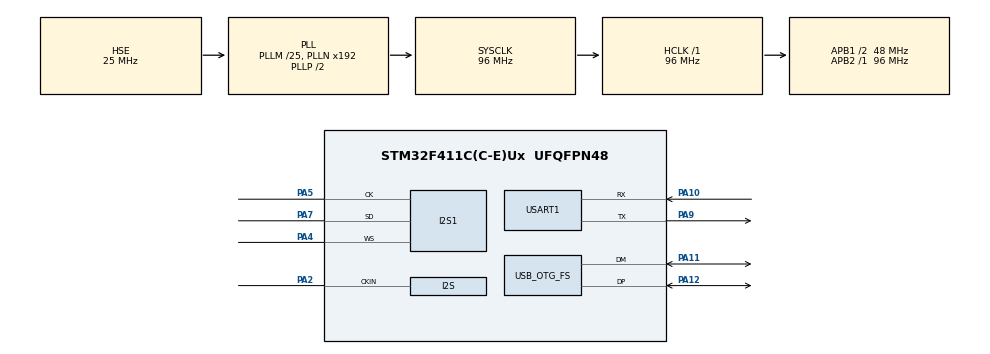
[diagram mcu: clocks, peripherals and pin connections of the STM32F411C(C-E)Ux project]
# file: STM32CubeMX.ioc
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Dma.Request0=SPI1_RX
Dma.SPI1_RX.0.Direction=DMA_PERIPH_TO_MEMORY
Dma.SPI1_RX.0.FIFOMode=DMA_FIFOMODE_ENABLE
Dma.SPI1_RX.0.FIFOThreshold=DMA_FIFO_THRESHOLD_HALFFULL
Dma.SPI1_RX.0.Instance=DMA2_Stream0
Dma.SPI1_RX.0.MemBurst=DMA_MBURST_SINGLE
Dma.SPI1_RX.0.MemDataAlignment=DMA_MDATAALIGN_HALFWORD
Dma.SPI1_RX.0.MemInc=DMA_MINC_ENABLE
Dma.SPI1_RX.0.Mode=DMA_CIRCULAR
Dma.SPI1_RX.0.PeriphBurst=DMA_PBURST_SINGLE
Dma.SPI1_RX.0.PeriphDataAlignment=DMA_PDATAALIGN_HALFWORD
Dma.SPI1_RX.0.PeriphInc=DMA_PINC_DISABLE
Dma.SPI1_RX.0.Priority=DMA_PRIORITY_HIGH
I2S1.AudioFreq=I2S_AUDIOFREQ_96K
I2S1.ClockSource=I2S_CLOCK_EXTERNAL
I2S1.DataFormat=I2S_DATAFORMAT_24B
I2S1.ErrorAudioFreq=-8.12 %
I2S1.FullDuplexMode=I2S_FULLDUPLEXMODE_DISABLE
I2S1.Instance=SPI$Index
I2S1.Mode=I2S_MODE_SLAVE_RX
I2S1.RealAudioFreq=88.2 KHz
I2S1.VirtualMode=I2S_MODE_SLAVE
Mcu.Family=STM32F4
Mcu.Name=STM32F411C(C-E)Ux
Mcu.Package=UFQFPN48
NVIC.DMA2_Stream0_IRQn=true\:8\:0\:true\:false\:true\:false\:true\:true
NVIC.PriorityGroup=NVIC_PRIORITYGROUP_4
NVIC.TIM5_IRQn=true\:15\:0\:false\:false\:true\:false\:true\:true
NVIC.TimeBase=TIM5_IRQn
NVIC.TimeBaseIP=TIM5
PA10.Mode=Asynchronous
PA10.Signal=USART1_RX
PA11.Mode=Device_Only
PA11.Signal=USB_OTG_FS_DM
PA12.Mode=Device_Only
PA12.Signal=USB_OTG_FS_DP
PA13.Mode=Serial_Wire
PA13.Signal=SYS_JTMS-SWDIO
PA14.Mode=Serial_Wire
PA14.Signal=SYS_JTCK-SWCLK
PA2.Mode=Audio_ClockIn
PA2.Signal=I2S_CKIN
PA4.Mode=Half_Duplex_Slave
PA4.Signal=I2S1_WS
PA5.Mode=Half_Duplex_Slave
PA5.Signal=I2S1_CK
PA7.Mode=Half_Duplex_Slave
PA7.Signal=I2S1_SD
PA9.Mode=Asynchronous
PA9.Signal=USART1_TX
PC14-OSC32_IN.Mode=LSE-External-Oscillator
PC14-OSC32_IN.Signal=RCC_OSC32_IN
PC15-OSC32_OUT.Mode=LSE-External-Oscillator
PC15-OSC32_OUT.Signal=RCC_OSC32_OUT
PH0\ -\ OSC_IN.Mode=HSE-External-Oscillator
PH0\ -\ OSC_IN.Signal=RCC_OSC_IN
PH1\ -\ OSC_OUT.Mode=HSE-External-Oscillator
PH1\ -\ OSC_OUT.Signal=RCC_OSC_OUT
ProjectManager.HeapSize=0x400
ProjectManager.StackSize=0x400
ProjectManager.TargetToolchain=MDK-ARM V5
RCC.48MHZClocksFreq_Value=48000000
RCC.AHBFreq_Value=96000000
RCC.APB1CLKDivider=RCC_HCLK_DIV2
RCC.APB1Freq_Value=48000000
RCC.APB1TimFreq_Value=96000000
RCC.APB2Freq_Value=96000000
RCC.APB2TimFreq_Value=96000000
RCC.CortexFreq_Value=96000000
RCC.EXTERNAL_CLOCK_VALUE=24567000
RCC.HCLKFreq_Value=96000000
RCC.HSE_VALUE=25000000
RCC.HSI_VALUE=16000000
RCC.I2SClockSource=I2S_CLOCK_EXTERNAL
RCC.PLLM=25
RCC.SYSCLKFreq_VALUE=96000000
RCC.SYSCLKSource=RCC_SYSCLKSOURCE_PLLCLK
RCC.VCOOutputFreq_Value=192000000
RTC.Format=RTC_FORMAT_BCD
USART1.VirtualMode=VM_ASYNC
USB_OTG_FS.VirtualMode=Device_Only
VP_RTC_VS_RTC_Activate.Mode=RTC_Enabled
VP_RTC_VS_RTC_Calendar.Mode=RTC_Calendar
VP_SYS_VS_tim5.Mode=TIM5
board=custom

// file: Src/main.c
/* USER CODE BEGIN Header */
/**
  ******************************************************************************
  * @file           : main.c
  * @brief          : Main program body
  ******************************************************************************
  * @attention
  *
  * Copyright (c) 2026 STMicroelectronics.
  * All rights reserved.
  *
  * This software is licensed under terms that can be found in the LICENSE file
  * in the root directory of this software component.
  * If no LICENSE file comes with this software, it is provided AS-IS.
  *
  ******************************************************************************
  */
/* USER CODE END Header */
#include "main.h"

I2S_HandleTypeDef hi2s1;
DMA_HandleTypeDef hdma_spi1_rx;

RTC_HandleTypeDef hrtc;

UART_HandleTypeDef huart1;

PCD_HandleTypeDef hpcd_USB_OTG_FS;

void SystemClock_Config(void);
static void MX_GPIO_Init(void);
static void MX_DMA_Init(void);
static void MX_RTC_Init(void);
static void MX_USART1_UART_Init(void);
static void MX_USB_OTG_FS_PCD_Init(void);
static void MX_I2S1_Init(void);
/* USER CODE BEGIN PFP */
extern void app_main(void);
/* USER CODE END PFP */

int main(void)
{

  /* MCU Configuration--------------------------------------------------------*/

  /* Reset of all peripherals, Initializes the Flash interface and the Systick. */
  HAL_Init();

  /* Configure the system clock */
  SystemClock_Config();

  /* USER CODE BEGIN SysInit */
  // 在 main 或时钟初始化后
  CoreDebug->DEMCR |= CoreDebug_DEMCR_TRCENA_Msk;  // 或 (*(volatile U32*)0xE000EDFC) |= (1<<24);
  DWT->CYCCNT = 0;
  DWT->CTRL  |= DWT_CTRL_CYCCNTENA_Msk;            // 或 DWT->CTRL |= (1 << 0);
  /* USER CODE END SysInit */

  /* Initialize all configured peripherals */
  MX_GPIO_Init();
  MX_DMA_Init();
  MX_RTC_Init();
  MX_USART1_UART_Init();
  MX_USB_OTG_FS_PCD_Init();
  MX_I2S1_Init();
  /* USER CODE BEGIN 2 */
  app_main();
  /* USER CODE END 2 */

  /* Infinite loop */
  while (1)
  {

  }
}

void SystemClock_Config(void)
{
  RCC_OscInitTypeDef RCC_OscInitStruct = {0};
  RCC_ClkInitTypeDef RCC_ClkInitStruct = {0};

  /** Configure the main internal regulator output voltage
  */
  __HAL_RCC_PWR_CLK_ENABLE();
  __HAL_PWR_VOLTAGESCALING_CONFIG(PWR_REGULATOR_VOLTAGE_SCALE1);

  /** Initializes the RCC Oscillators according to the specified parameters
  * in the RCC_OscInitTypeDef structure.
  */
  RCC_OscInitStruct.OscillatorType = RCC_OSCILLATORTYPE_LSI|RCC_OSCILLATORTYPE_HSE;
  RCC_OscInitStruct.HSEState = RCC_HSE_ON;
  RCC_OscInitStruct.LSIState = RCC_LSI_ON;
  RCC_OscInitStruct.PLL.PLLState = RCC_PLL_ON;
  RCC_OscInitStruct.PLL.PLLSource = RCC_PLLSOURCE_HSE;
  RCC_OscInitStruct.PLL.PLLM = 25;
  RCC_OscInitStruct.PLL.PLLN = 192;
  RCC_OscInitStruct.PLL.PLLP = RCC_PLLP_DIV2;
  RCC_OscInitStruct.PLL.PLLQ = 4;
  if (HAL_RCC_OscConfig(&RCC_OscInitStruct) != HAL_OK)
  {
    Error_Handler();
  }

  /** Initializes the CPU, AHB and APB buses clocks
  */
  RCC_ClkInitStruct.ClockType = RCC_CLOCKTYPE_HCLK|RCC_CLOCKTYPE_SYSCLK
                              |RCC_CLOCKTYPE_PCLK1|RCC_CLOCKTYPE_PCLK2;
  RCC_ClkInitStruct.SYSCLKSource = RCC_SYSCLKSOURCE_PLLCLK;
  RCC_ClkInitStruct.AHBCLKDivider = RCC_SYSCLK_DIV1;
  RCC_ClkInitStruct.APB1CLKDivider = RCC_HCLK_DIV2;
  RCC_ClkInitStruct.APB2CLKDivider = RCC_HCLK_DIV1;

  if (HAL_RCC_ClockConfig(&RCC_ClkInitStruct, FLASH_LATENCY_3) != HAL_OK)
  {
    Error_Handler();
  }
}

static void MX_I2S1_Init(void)
{

  hi2s1.Instance = SPI1;
  hi2s1.Init.Mode = I2S_MODE_SLAVE_RX;
  hi2s1.Init.Standard = I2S_STANDARD_PHILIPS;
  hi2s1.Init.DataFormat = I2S_DATAFORMAT_24B;
  hi2s1.Init.MCLKOutput = I2S_MCLKOUTPUT_DISABLE;
  hi2s1.Init.AudioFreq = I2S_AUDIOFREQ_96K;
  hi2s1.Init.CPOL = I2S_CPOL_LOW;
  hi2s1.Init.ClockSource = I2S_CLOCK_EXTERNAL;
  hi2s1.Init.FullDuplexMode = I2S_FULLDUPLEXMODE_DISABLE;
  if (HAL_I2S_Init(&hi2s1) != HAL_OK)
  {
    Error_Handler();
  }

}

static void MX_RTC_Init(void)
{

  RTC_TimeTypeDef sTime = {0};
  RTC_DateTypeDef sDate = {0};

  /** Initialize RTC Only
  */
  hrtc.Instance = RTC;
  hrtc.Init.HourFormat = RTC_HOURFORMAT_24;
  hrtc.Init.AsynchPrediv = 127;
  hrtc.Init.SynchPrediv = 255;
  hrtc.Init.OutPut = RTC_OUTPUT_DISABLE;
  hrtc.Init.OutPutPolarity = RTC_OUTPUT_POLARITY_HIGH;
  hrtc.Init.OutPutType = RTC_OUTPUT_TYPE_OPENDRAIN;
  if (HAL_RTC_Init(&hrtc) != HAL_OK)
  {
    Error_Handler();
  }

  /** Initialize RTC and set the Time and Date
  */
  sTime.Hours = 0x0;
  sTime.Minutes = 0x0;
  sTime.Seconds = 0x0;
  sTime.DayLightSaving = RTC_DAYLIGHTSAVING_NONE;
  sTime.StoreOperation = RTC_STOREOPERATION_RESET;
  if (HAL_RTC_SetTime(&hrtc, &sTime, RTC_FORMAT_BCD) != HAL_OK)
  {
    Error_Handler();
  }
  sDate.WeekDay = RTC_WEEKDAY_MONDAY;
  sDate.Month = RTC_MONTH_JANUARY;
  sDate.Date = 0x1;
  sDate.Year = 0x0;

  if (HAL_RTC_SetDate(&hrtc, &sDate, RTC_FORMAT_BCD) != HAL_OK)
  {
    Error_Handler();
  }

}

static void MX_USART1_UART_Init(void)
{

  huart1.Instance = USART1;
  huart1.Init.BaudRate = 115200;
  huart1.Init.WordLength = UART_WORDLENGTH_8B;
  huart1.Init.StopBits = UART_STOPBITS_1;
  huart1.Init.Parity = UART_PARITY_NONE;
  huart1.Init.Mode = UART_MODE_TX_RX;
  huart1.Init.HwFlowCtl = UART_HWCONTROL_NONE;
  huart1.Init.OverSampling = UART_OVERSAMPLING_16;
  if (HAL_UART_Init(&huart1) != HAL_OK)
  {
    Error_Handler();
  }

}

static void MX_USB_OTG_FS_PCD_Init(void)
{

  hpcd_USB_OTG_FS.Instance = USB_OTG_FS;
  hpcd_USB_OTG_FS.Init.dev_endpoints = 4;
  hpcd_USB_OTG_FS.Init.speed = PCD_SPEED_FULL;
  hpcd_USB_OTG_FS.Init.dma_enable = DISABLE;
  hpcd_USB_OTG_FS.Init.phy_itface = PCD_PHY_EMBEDDED;
  hpcd_USB_OTG_FS.Init.Sof_enable = DISABLE;
  hpcd_USB_OTG_FS.Init.low_power_enable = DISABLE;
  hpcd_USB_OTG_FS.Init.lpm_enable = DISABLE;
  hpcd_USB_OTG_FS.Init.vbus_sensing_enable = DISABLE;
  hpcd_USB_OTG_FS.Init.use_dedicated_ep1 = DISABLE;
  if (HAL_PCD_Init(&hpcd_USB_OTG_FS) != HAL_OK)
  {
    Error_Handler();
  }

}

static void MX_DMA_Init(void)
{

  /* DMA controller clock enable */
  __HAL_RCC_DMA2_CLK_ENABLE();

  /* DMA interrupt init */
  /* DMA2_Stream0_IRQn interrupt configuration */
  HAL_NVIC_SetPriority(DMA2_Stream0_IRQn, 8, 0);
  HAL_NVIC_EnableIRQ(DMA2_Stream0_IRQn);

}

static void MX_GPIO_Init(void)
{
  GPIO_InitTypeDef GPIO_InitStruct = {0};

  /* GPIO Ports Clock Enable */
  __HAL_RCC_GPIOC_CLK_ENABLE();
  __HAL_RCC_GPIOH_CLK_ENABLE();
  __HAL_RCC_GPIOA_CLK_ENABLE();

  /*Configure GPIO pin : PA2 */
  GPIO_InitStruct.Pin = GPIO_PIN_2;
  GPIO_InitStruct.Mode = GPIO_MODE_AF_PP;
  GPIO_InitStruct.Pull = GPIO_NOPULL;
  GPIO_InitStruct.Speed = GPIO_SPEED_FREQ_LOW;
  GPIO_InitStruct.Alternate = GPIO_AF5_SPI1;
  HAL_GPIO_Init(GPIOA, &GPIO_InitStruct);

}

void HAL_TIM_PeriodElapsedCallback(TIM_HandleTypeDef *htim)
{
  if (htim->Instance == TIM5)
  {
    HAL_IncTick();
  }
}

void Error_Handler(void)
{
  __disable_irq();
  while (1)
  {
  }
}
